VERSION "created by canmatrix"

NS_ :

BS_:

BU_: User ADM_PC_LL25 ADM_PC_BC25 ADM_PC_BP25 ADM_PC_BI25

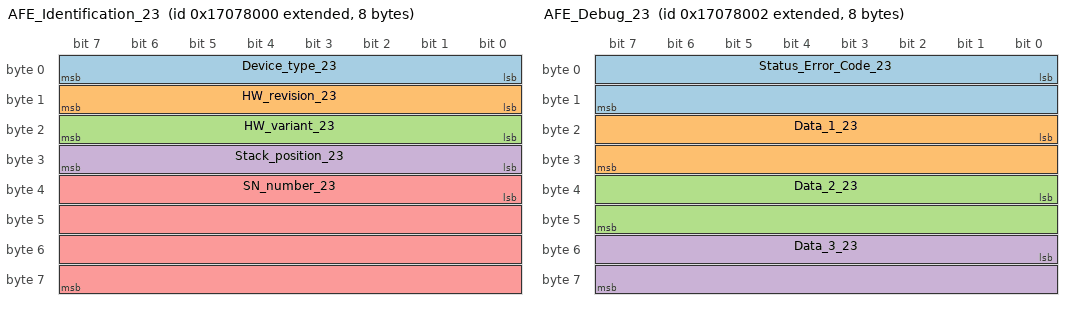
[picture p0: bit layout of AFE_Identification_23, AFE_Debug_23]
BO_ 2533851136 AFE_Identification_23: 8 ADM_PC_BP25
 SG_ Device_type_23 : 0|8@1+ (1,0) [0|255] "" Vector__XXX
 SG_ HW_revision_23 : 8|8@1+ (1,0) [0|255] "" Vector__XXX
 SG_ HW_variant_23 : 16|8@1+ (1,0) [0|255] "" Vector__XXX
 SG_ Stack_position_23 : 24|8@1+ (1,0) [0|255] "" Vector__XXX
 SG_ SN_number_23 : 32|32@1+ (1,0) [0|4294967295] "" Vector__XXX

BO_ 2533851137 AFE_FwInfo_23: 8 ADM_PC_BP25
 SG_ FW_info_mux_23 M : 56|8@1+ (1,0) [0|255] "" Vector__XXX
 SG_ FW_revision_0_23 m0 : 0|8@1+ (1,0) [0|255] "" Vector__XXX
 SG_ FW_revision_1_23 m0 : 8|8@1+ (1,0) [0|255] "" Vector__XXX
 SG_ FW_revision_2_23 m0 : 16|8@1+ (1,0) [0|255] "" Vector__XXX
 SG_ FW_revision_3_23 m0 : 24|8@1+ (1,0) [0|255] "" Vector__XXX
 SG_ FW_revision_4_23 m0 : 32|8@1+ (1,0) [0|255] "" Vector__XXX
 SG_ FW_revision_5_23 m0 : 40|8@1+ (1,0) [0|255] "" Vector__XXX
 SG_ FW_revision_6_23 m0 : 48|8@1+ (1,0) [0|255] "" Vector__XXX
 SG_ FW_revision_7_23 m1 : 0|8@1+ (1,0) [0|255] "" Vector__XXX
 SG_ FW_revision_8_23 m1 : 8|8@1+ (1,0) [0|255] "" Vector__XXX
 SG_ FW_revision_9_23 m1 : 16|8@1+ (1,0) [0|255] "" Vector__XXX
 SG_ FW_revision_10_23 m1 : 24|8@1+ (1,0) [0|255] "" Vector__XXX
 SG_ FW_revision_11_23 m1 : 32|8@1+ (1,0) [0|255] "" Vector__XXX
 SG_ FW_revision_12_23 m1 : 40|8@1+ (1,0) [0|255] "" Vector__XXX
 SG_ FW_revision_13_23 m1 : 48|8@1+ (1,0) [0|255] "" Vector__XXX
 SG_ FW_datecode_0_23 m2 : 0|8@1+ (1,0) [0|255] "" Vector__XXX
 SG_ FW_datecode_1_23 m2 : 8|8@1+ (1,0) [0|255] "" Vector__XXX
 SG_ FW_datecode_2_23 m2 : 16|8@1+ (1,0) [0|255] "" Vector__XXX
 SG_ FW_datecode_3_23 m2 : 24|8@1+ (1,0) [0|255] "" Vector__XXX
 SG_ FW_datecode_4_23 m2 : 32|8@1+ (1,0) [0|255] "" Vector__XXX
 SG_ FW_datecode_5_23 m2 : 40|8@1+ (1,0) [0|255] "" Vector__XXX
 SG_ FW_datecode_6_23 m2 : 48|8@1+ (1,0) [0|255] "" Vector__XXX
 SG_ FW_datecode_7_23 m3 : 0|8@1+ (1,0) [0|255] "" Vector__XXX
 SG_ FW_datecode_8_23 m3 : 8|8@1+ (1,0) [0|255] "" Vector__XXX
 SG_ FW_datecode_9_23 m3 : 16|8@1+ (1,0) [0|255] "" Vector__XXX
 SG_ FW_datecode_10_23 m3 : 24|8@1+ (1,0) [0|255] "" Vector__XXX
 SG_ FW_datecode_11_23 m3 : 32|8@1+ (1,0) [0|255] "" Vector__XXX
 SG_ FW_datecode_12_23 m3 : 40|8@1+ (1,0) [0|255] "" Vector__XXX
 SG_ FW_datecode_13_23 m3 : 48|8@1+ (1,0) [0|255] "" Vector__XXX

BO_ 2533851149 _AFE_Boot_FwInfo_23: 8 ADM_PC_BP25
 SG_ Boot_FW_info_mux_23 M : 56|8@1+ (1,0) [0|255] "" Vector__XXX
 SG_ FW_revision_0_23 m0 : 0|8@1+ (1,0) [0|255] "" Vector__XXX
 SG_ FW_revision_1_23 m0 : 8|8@1+ (1,0) [0|255] "" Vector__XXX
 SG_ FW_revision_2_23 m0 : 16|8@1+ (1,0) [0|255] "" Vector__XXX
 SG_ FW_revision_3_23 m0 : 24|8@1+ (1,0) [0|255] "" Vector__XXX
 SG_ FW_revision_4_23 m0 : 32|8@1+ (1,0) [0|255] "" Vector__XXX
 SG_ FW_revision_5_23 m0 : 40|8@1+ (1,0) [0|255] "" Vector__XXX
 SG_ FW_revision_6_23 m0 : 48|8@1+ (1,0) [0|255] "" Vector__XXX
 SG_ FW_revision_7_23 m1 : 0|8@1+ (1,0) [0|255] "" Vector__XXX
 SG_ FW_revision_8_23 m1 : 8|8@1+ (1,0) [0|255] "" Vector__XXX
 SG_ FW_revision_9_23 m1 : 16|8@1+ (1,0) [0|255] "" Vector__XXX
 SG_ FW_revision_10_23 m1 : 24|8@1+ (1,0) [0|255] "" Vector__XXX
 SG_ FW_revision_11_23 m1 : 32|8@1+ (1,0) [0|255] "" Vector__XXX
 SG_ FW_revision_12_23 m1 : 40|8@1+ (1,0) [0|255] "" Vector__XXX
 SG_ FW_revision_13_23 m1 : 48|8@1+ (1,0) [0|255] "" Vector__XXX
 SG_ FW_datecode_0_23 m2 : 0|8@1+ (1,0) [0|255] "" Vector__XXX
 SG_ FW_datecode_1_23 m2 : 8|8@1+ (1,0) [0|255] "" Vector__XXX
 SG_ FW_datecode_2_23 m2 : 16|8@1+ (1,0) [0|255] "" Vector__XXX
 SG_ FW_datecode_3_23 m2 : 24|8@1+ (1,0) [0|255] "" Vector__XXX
 SG_ FW_datecode_4_23 m2 : 32|8@1+ (1,0) [0|255] "" Vector__XXX
 SG_ FW_datecode_5_23 m2 : 40|8@1+ (1,0) [0|255] "" Vector__XXX
 SG_ FW_datecode_6_23 m2 : 48|8@1+ (1,0) [0|255] "" Vector__XXX
 SG_ FW_datecode_7_23 m3 : 0|8@1+ (1,0) [0|255] "" Vector__XXX
 SG_ FW_datecode_8_23 m3 : 8|8@1+ (1,0) [0|255] "" Vector__XXX
 SG_ FW_datecode_9_23 m3 : 16|8@1+ (1,0) [0|255] "" Vector__XXX
 SG_ FW_datecode_10_23 m3 : 24|8@1+ (1,0) [0|255] "" Vector__XXX
 SG_ FW_datecode_11_23 m3 : 32|8@1+ (1,0) [0|255] "" Vector__XXX
 SG_ FW_datecode_12_23 m3 : 40|8@1+ (1,0) [0|255] "" Vector__XXX
 SG_ FW_datecode_13_23 m3 : 48|8@1+ (1,0) [0|255] "" Vector__XXX

BO_ 2533851138 AFE_Debug_23: 8 ADM_PC_BP25
 SG_ Status_Error_Code_23 : 0|16@1+ (1,0) [0|65535] "" Vector__XXX
 SG_ Data_1_23 : 16|16@1+ (1,0) [0|65535] "" Vector__XXX
 SG_ Data_2_23 : 32|16@1+ (1,0) [0|65535] "" Vector__XXX
 SG_ Data_3_23 : 48|16@1+ (1,0) [0|65535] "" Vector__XXX

BO_ 2533851143 AFE_Status_23: 8 ADM_PC_BP25
 SG_ Running_23 : 0|1@1+ (1,0) [0|1] "" Vector__XXX
 SG_ PWM_23 : 1|1@1+ (1,0) [0|1] "" Vector__XXX
 SG_ Current_dc_loop_mode_23 : 2|1@1+ (1,0) [0|1] "" Vector__XXX
 SG_ Current_ac_loop_mode_23 : 3|1@1+ (1,0) [0|1] "" Vector__XXX
 SG_ Buck_23 : 5|1@1+ (1,0) [0|1] "" Vector__XXX
 SG_ Boost_23 : 6|1@1+ (1,0) [0|1] "" Vector__XXX
 SG_ Precharge_dc_buck_mode_23 : 7|1@1+ (1,0) [0|1] "" Vector__XXX
 SG_ Precharge_dc_boost_mode_23 : 8|1@1+ (1,0) [0|1] "" Vector__XXX
 SG_ Rectifier_3ph_23 : 9|1@1+ (1,0) [0|1] "" Vector__XXX
 SG_ Stack_mode_23 : 10|1@1+ (1,0) [0|1] "" Vector__XXX
 SG_ Master_23 : 11|1@1+ (1,0) [0|1] "" Vector__XXX
 SG_ Slave_23 : 12|1@1+ (1,0) [0|1] "" Vector__XXX
 SG_ Inverter_1ph_23 : 13|1@1+ (1,0) [0|1] "" Vector__XXX
 SG_ Boost_Neutral_23 : 14|1@1+ (1,0) [0|1] "" Vector__XXX
 SG_ Rectifier_1ph_23 : 15|1@1+ (1,0) [0|1] "" Vector__XXX
 SG_ Inverter_3ph_23 : 16|1@1+ (1,0) [0|1] "" Vector__XXX
 SG_ Ready_23 : 17|1@1+ (1,0) [0|1] "" Vector__XXX
 SG_ Inverter_1ph_Sync_23 : 18|1@1+ (1,0) [0|1] "" Vector__XXX
 SG_ Neutral_23 : 19|1@1+ (1,0) [0|1] "" Vector__XXX
 SG_ Rectifier_1ph_Buck_23 : 20|1@1+ (1,0) [0|1] "" Vector__XXX
 SG_ Inverter_1ph_Boost_23 : 21|1@1+ (1,0) [0|1] "" Vector__XXX
 SG_ Rectifier_distributed_23 : 22|1@1+ (1,0) [0|1] "" Vector__XXX
 SG_ MPPT_buck_23 : 23|1@1+ (1,0) [0|1] "" Vector__XXX
 SG_ MPPT_boost_23 : 24|1@1+ (1,0) [0|1] "" Vector__XXX
 SG_ Buck_2p_float_23 : 25|1@1+ (1,0) [0|1] "" Vector__XXX
 SG_ Inverter_1ph_Distributed_23 : 26|1@1+ (1,0) [0|1] "" Vector__XXX

BO_ 2533851142 AFE_Faults_23: 3 ADM_PC_BP25
 SG_ Protection_trip_internal_23 : 0|1@1+ (1,0) [0|1] "" Vector__XXX
 SG_ Protection_trip_external_23 : 1|1@1+ (1,0) [0|1] "" Vector__XXX
 SG_ Phase_U_overcurrent_23 : 2|1@1+ (1,0) [0|1] "" Vector__XXX
 SG_ Phase_U_overvoltage_23 : 3|1@1+ (1,0) [0|1] "" Vector__XXX
 SG_ Phase_U_undervoltage_23 : 4|1@1+ (1,0) [0|1] "" Vector__XXX
 SG_ Phase_V_overvoltage_23 : 5|1@1+ (1,0) [0|1] "" Vector__XXX
 SG_ Phase_V_undervoltage_23 : 6|1@1+ (1,0) [0|1] "" Vector__XXX
 SG_ Phase_V_overcurrent_23 : 7|1@1+ (1,0) [0|1] "" Vector__XXX
 SG_ Phase_W_overvoltage_23 : 8|1@1+ (1,0) [0|1] "" Vector__XXX
 SG_ Phase_W_undervoltage_23 : 9|1@1+ (1,0) [0|1] "" Vector__XXX
 SG_ Phase_W_overcurrent_23 : 10|1@1+ (1,0) [0|1] "" Vector__XXX
 SG_ DC_undervoltage_23 : 11|1@1+ (1,0) [0|1] "" Vector__XXX
 SG_ DC_overvoltage_23 : 12|1@1+ (1,0) [0|1] "" Vector__XXX
 SG_ MOSFET_overtemperature_23 : 13|1@1+ (1,0) [0|1] "" Vector__XXX
 SG_ Inductor_overtemperature_23 : 14|1@1+ (1,0) [0|1] "" Vector__XXX
 SG_ Keep_Alive_not_served_23 : 15|1@1+ (1,0) [0|1] "" Vector__XXX
 SG_ PLL_not_locked_23 : 16|1@1+ (1,0) [0|1] "" Vector__XXX
 SG_ NFO_23 : 20|1@1+ (1,0) [0|1] "" Vector__XXX
 SG_ Measurement_system_failure_23 : 21|1@1+ (1,0) [0|1] "" Vector__XXX
 SG_ EEPROM_failure_23 : 22|1@1+ (1,0) [0|1] "" Vector__XXX
 SG_ System_23 : 23|1@1+ (1,0) [0|1] "" Vector__XXX

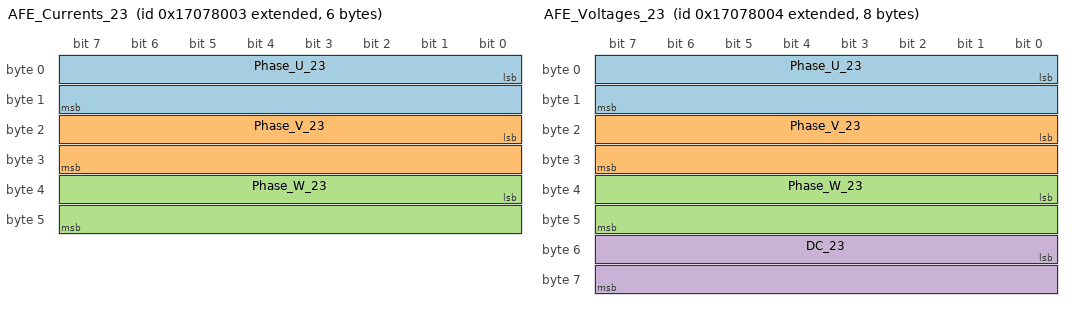
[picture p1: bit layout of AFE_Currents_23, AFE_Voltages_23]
BO_ 2533851139 AFE_Currents_23: 6 ADM_PC_BP25
 SG_ Phase_U_23 : 0|16@1- (0.01,0) [-327.68|327.67] "A" Vector__XXX
 SG_ Phase_V_23 : 16|16@1- (0.01,0) [-327.68|327.67] "A" Vector__XXX
 SG_ Phase_W_23 : 32|16@1- (0.01,0) [-327.68|327.67] "A" Vector__XXX

BO_ 2533851152 AFE_DC_Bus_current_23: 2 ADM_PC_BP25
 SG_ Bus_current_23 : 0|16@1- (0.01,0) [-327.68|327.67] "A" Vector__XXX

BO_ 2533851150 _AFE_Broadcast_23: 8 ADM_PC_BP25
 SG_ Diagnostics_Index_23 M : 56|8@1+ (1,0) [0|255] "" Vector__XXX
 SG_ Phase_U_23 m1 : 8|16@1- (0.01,0) [-327.68|327.67] "A" ADM_PC_BP25
 SG_ Phase_V_23 m1 : 24|16@1- (0.01,0) [-327.68|327.67] "A" ADM_PC_BP25
 SG_ Phase_W_23 m1 : 40|16@1- (0.01,0) [-327.68|327.67] "A" ADM_PC_BP25
 SG_ Stack_position_23 : 0|5@1+ (1,0) [0|31] "" ADM_PC_BP25
 SG_ Group_ID_23 : 5|3@1+ (1,0) [0|7] "" ADM_PC_BP25

BO_ 2533851140 AFE_Voltages_23: 8 ADM_PC_BP25
 SG_ Phase_U_23 : 0|16@1- (0.1,0) [-3276.8|3276.7] "V" Vector__XXX
 SG_ Phase_V_23 : 16|16@1- (0.1,0) [-3276.8|3276.7] "V" Vector__XXX
 SG_ Phase_W_23 : 32|16@1- (0.1,0) [-3276.8|3276.7] "V" Vector__XXX
 SG_ DC_23 : 48|16@1- (0.1,0) [-3276.8|3276.7] "V" Vector__XXX

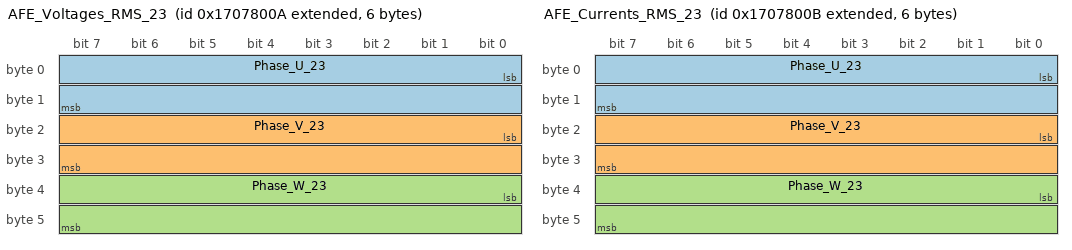
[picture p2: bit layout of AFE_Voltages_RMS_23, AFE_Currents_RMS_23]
BO_ 2533851146 AFE_Voltages_RMS_23: 6 ADM_PC_BP25
 SG_ Phase_U_23 : 0|16@1+ (0.1,0) [0|6553.5] "V" Vector__XXX
 SG_ Phase_V_23 : 16|16@1+ (0.1,0) [0|6553.5] "V" Vector__XXX
 SG_ Phase_W_23 : 32|16@1+ (0.1,0) [0|6553.5] "V" Vector__XXX

BO_ 2533851147 AFE_Currents_RMS_23: 6 ADM_PC_BP25
 SG_ Phase_U_23 : 0|16@1+ (0.01,0) [0.00|655.35] "A" Vector__XXX
 SG_ Phase_V_23 : 16|16@1+ (0.01,0) [0.00|655.35] "A" Vector__XXX
 SG_ Phase_W_23 : 32|16@1+ (0.01,0) [0.00|655.35] "A" Vector__XXX

BO_ 2533851148 AFE_Mains_23: 4 ADM_PC_BP25
 SG_ Frequency_23 : 0|16@1+ (0.01,0) [0.00|655.35] "Hz" Vector__XXX
 SG_ Phase_23 : 16|16@1- (0.1,0) [-3276.8|3276.7] "Deg." Vector__XXX

BO_ 2533851141 AFE_Temperatures_23: 4 ADM_PC_BP25
 SG_ Temp_Bridge_23 : 0|16@1- (0.01,0) [-327.68|327.67] "°C" Vector__XXX
 SG_ Temp_Inductors_23 : 16|16@1- (0.01,0) [-327.68|327.67] "°C" Vector__XXX

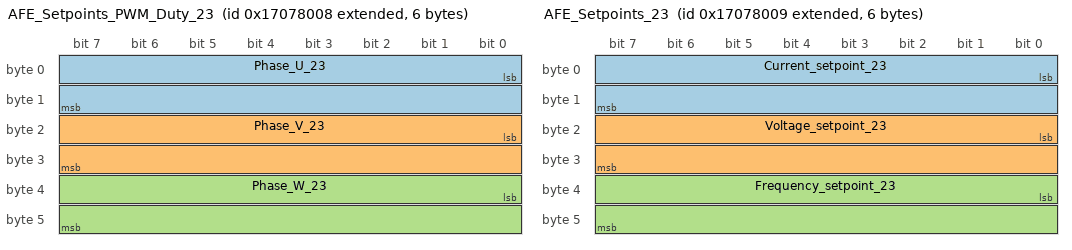
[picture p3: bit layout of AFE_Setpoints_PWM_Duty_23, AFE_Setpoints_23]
BO_ 2533851144 AFE_Setpoints_PWM_Duty_23: 6 ADM_PC_BP25
 SG_ Phase_U_23 : 0|16@1+ (0.001525902,0) [0E-009|99.999987570] "%" Vector__XXX
 SG_ Phase_V_23 : 16|16@1+ (0.001525902,0) [0E-009|99.999987570] "%" Vector__XXX
 SG_ Phase_W_23 : 32|16@1+ (0.001525902,0) [0E-009|99.999987570] "%" Vector__XXX

BO_ 2533851145 AFE_Setpoints_23: 6 ADM_PC_BP25
 SG_ Current_setpoint_23 : 0|16@1- (0.01,0) [-327.68|327.67] "A" Vector__XXX
 SG_ Voltage_setpoint_23 : 16|16@1+ (0.1,0) [0|6553.5] "V" Vector__XXX
 SG_ Frequency_setpoint_23 : 32|16@1+ (0.01,0) [0.00|655.35] "Hz" Vector__XXX

BO_ 2533818464 AFE_Keep_Alive_23: 1 User
 SG_ Keep_Alive_Enable_23 : 0|1@1+ (1,0) [0|1] "" ADM_PC_BP25

BO_ 2533818432 AFE_Mode_Control_23: 8 User
 SG_ Converter_ON_23 : 0|1@1+ (1,0) [0|1] "" ADM_PC_BP25
 SG_ PWM_ON_23 : 1|1@1+ (1,0) [0|1] "" ADM_PC_BP25
 SG_ DC_Current_feedback_ON_23 : 2|1@1+ (1,0) [0|1] "" ADM_PC_BP25
 SG_ AC_Current_feedback_ON_23 : 3|1@1+ (1,0) [0|1] "" ADM_PC_BP25
 SG_ Buck_ON_23 : 5|1@1+ (1,0) [0|1] "" ADM_PC_BP25
 SG_ Boost_ON_23 : 6|1@1+ (1,0) [0|1] "" ADM_PC_BP25
 SG_ Rectifier_3ph_ON_23 : 9|1@1+ (1,0) [0|1] "" ADM_PC_BP25
 SG_ Inverter_1ph_ON_23 : 10|1@1+ (1,0) [0|1] "" ADM_PC_BP25
 SG_ Rectifier_1ph_ON_23 : 11|1@1+ (1,0) [0|1] "" ADM_PC_BP25
 SG_ Boost_Neutral_ON_23 : 12|1@1+ (1,0) [0|1] "" ADM_PC_BP25
 SG_ Inverter_3ph_ON_23 : 13|1@1+ (1,0) [0|1] "" ADM_PC_BP25
 SG_ Inverter_1ph_Sync_ON_23 : 14|1@1+ (1,0) [0|1] "" ADM_PC_BP25
 SG_ Neutral_ON_23 : 15|1@1+ (1,0) [0|1] "" ADM_PC_BP25
 SG_ Rectifier_1ph_Buck_ON_23 : 16|1@1+ (1,0) [0|1] "" ADM_PC_BP25
 SG_ Inverter_1ph_Boost_ON_23 : 17|1@1+ (1,0) [0|1] "" ADM_PC_BP25
 SG_ Rectifier_Distributed_ON_23 : 18|1@1+ (1,0) [0|1] "" ADM_PC_BP25
 SG_ MPPT_buck_ON_23 : 19|1@1+ (1,0) [0|1] "" ADM_PC_BP25
 SG_ MPPT_boost_ON_23 : 20|1@1+ (1,0) [0|1] "" ADM_PC_BP25
 SG_ Buck_2p_float_ON_23 : 21|1@1+ (1,0) [0|1] "" ADM_PC_BP25
 SG_ Inverter_1ph_Distributed_ON_23 : 22|1@1+ (1,0) [0|1] "" ADM_PC_BP25

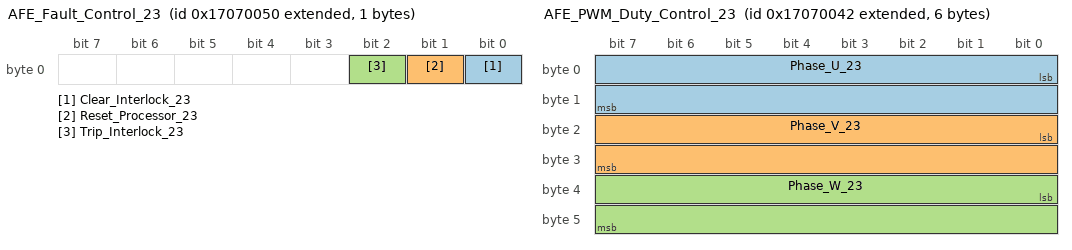
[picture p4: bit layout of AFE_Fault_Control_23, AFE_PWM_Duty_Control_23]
BO_ 2533818448 AFE_Fault_Control_23: 1 User
 SG_ Clear_Interlock_23 : 0|1@1+ (1,0) [0|1] "" ADM_PC_BP25
 SG_ Reset_Processor_23 : 1|1@1+ (1,0) [0|1] "" ADM_PC_BP25
 SG_ Trip_Interlock_23 : 2|1@1+ (1,0) [0|1] "" ADM_PC_BP25

BO_ 2533818433 AFE_Reactive_Current_Setpoint_Co: 2 User
 SG_ Reactive_current_setpoint_23 : 0|16@1- (0.01,0) [-150|150] "A" ADM_PC_BP25

BO_ 2533818434 AFE_PWM_Duty_Control_23: 6 User
 SG_ Phase_U_23 : 0|16@1+ (0.001525902,0) [0E-009|99.999987570] "%" ADM_PC_BP25
 SG_ Phase_V_23 : 16|16@1+ (0.001525902,0) [0E-009|99.999987570] "%" ADM_PC_BP25
 SG_ Phase_W_23 : 32|16@1+ (0.001525902,0) [0E-009|99.999987570] "%" ADM_PC_BP25

BO_ 2533818435 AFE_Current_Setpoint_Control_23: 2 User
 SG_ Current_setpoint_23 : 0|16@1- (0.01,0) [-150|150] "A" ADM_PC_BP25

BO_ 2533818436 AFE_Voltage_Setpoint_Control_23: 2 User
 SG_ Voltage_setpoint_23 : 0|16@1+ (0.1,0) [0|1500] "V" ADM_PC_BP25

BO_ 2533818440 AFE_Frequency_Setpoint_Control_2: 2 User
 SG_ Frequency_setpoint_23 : 0|16@1+ (0.01,0) [40|70] "Hz" ADM_PC_BP25

BO_ 2533818441 AFE_Phase_Setpoint_Control_23: 2 User
 SG_ Phase_setpoint_23 : 0|16@1+ (1,0) [0|360] "deg" ADM_PC_BP25

BO_ 2533818480 AFE_Rectifier_Setpoint_Control_2: 8 User
 SG_ Voltage_setpoint_2_23 : 0|16@1+ (0.1,0) [0|1500] "V" ADM_PC_BP25
 SG_ Current_setpoint_2_23 : 16|16@1- (0.01,0) [-150|150] "A" ADM_PC_BP25

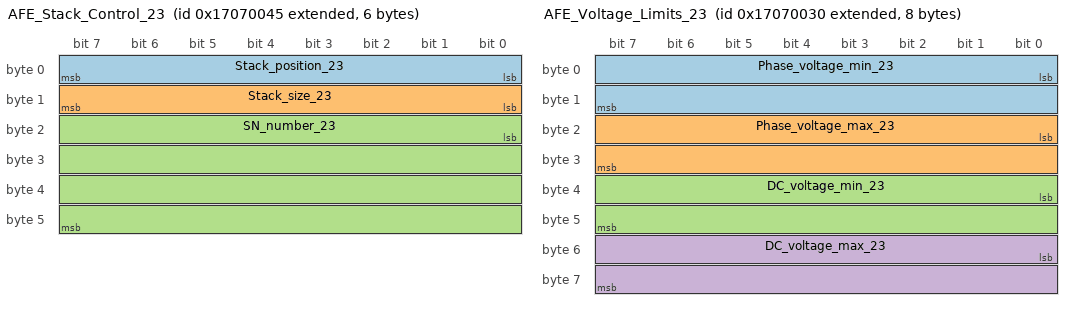
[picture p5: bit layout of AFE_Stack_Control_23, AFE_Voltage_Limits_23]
BO_ 2533818437 AFE_Stack_Control_23: 6 User
 SG_ Stack_position_23 : 0|8@1+ (1,0) [0|255] "" ADM_PC_BP25
 SG_ Stack_size_23 : 8|8@1+ (1,0) [0|255] "" ADM_PC_BP25
 SG_ SN_number_23 : 16|32@1+ (1,0) [0|4294967295] "" ADM_PC_BP25

BO_ 2533818416 AFE_Voltage_Limits_23: 8 User
 SG_ Phase_voltage_min_23 : 0|16@1- (0.1,0) [0|3276.7] "V" ADM_PC_BP25
 SG_ Phase_voltage_max_23 : 16|16@1- (0.1,0) [-3276.8|850] "V" ADM_PC_BP25
 SG_ DC_voltage_min_23 : 32|16@1- (0.1,0) [0|3276.7] "V" ADM_PC_BP25
 SG_ DC_voltage_max_23 : 48|16@1- (0.1,0) [-3276.8|850] "V" ADM_PC_BP25

BO_ 2533818417 AFE_Current_Limits_23: 4 User
 SG_ Phase_current_min_23 : 0|16@1- (0.01,0) [-60|60] "A" ADM_PC_BP25
 SG_ Phase_current_max_23 : 16|16@1- (0.01,0) [-60|60] "A" ADM_PC_BP25

BO_ 2533818444 AFE_Group_Control_23: 1 User
 SG_ Group_ID_23 : 0|8@1+ (1,0) [0|255] "" ADM_PC_BP25

BO_ 2533851151 AFE_Group_Info_23: 1 ADM_PC_BP25
 SG_ Group_ID_23 : 0|8@1+ (1,0) [0|255] "" Vector__XXX

BO_ 2533818465 AFE_System_Flags_Control_23: 8 User
 SG_ Factory_mode_23 : 0|1@1+ (1,0) [0|1] "" ADM_PC_BP25
 SG_ Silent_CAN_mode_23 : 1|1@1+ (1,0) [0|1] "" ADM_PC_BP25

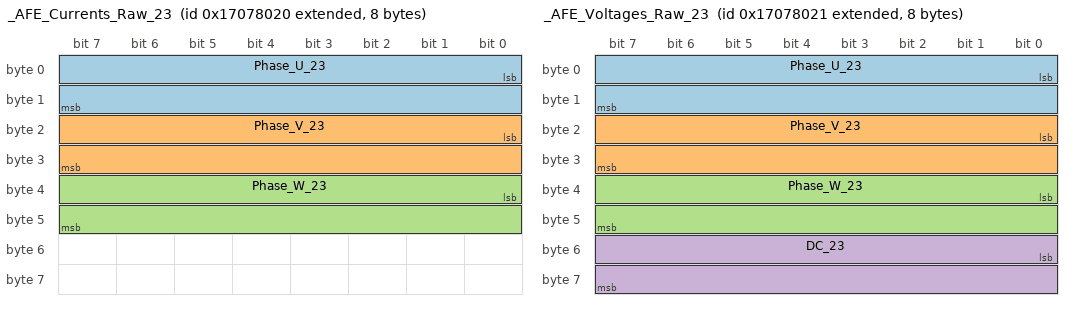
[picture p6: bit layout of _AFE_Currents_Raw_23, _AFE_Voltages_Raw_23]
BO_ 2533851168 _AFE_Currents_Raw_23: 8 ADM_PC_BP25
 SG_ Phase_U_23 : 0|16@1- (1,0) [-32768|32767] "" Vector__XXX
 SG_ Phase_V_23 : 16|16@1- (1,0) [-32768|32767] "" Vector__XXX
 SG_ Phase_W_23 : 32|16@1- (1,0) [-32768|32767] "" Vector__XXX

BO_ 2533851169 _AFE_Voltages_Raw_23: 8 ADM_PC_BP25
 SG_ Phase_U_23 : 0|16@1- (1,0) [-32768|32767] "" Vector__XXX
 SG_ Phase_V_23 : 16|16@1- (1,0) [-32768|32767] "" Vector__XXX
 SG_ Phase_W_23 : 32|16@1- (1,0) [-32768|32767] "" Vector__XXX
 SG_ DC_23 : 48|16@1- (1,0) [-32768|32767] "" Vector__XXX

BO_ 2533818442 _AFE_ADC_Calibration_Mode_23: 1 User
 SG_ Calibration_Index_23 M : 2|5@1+ (1,0) [0|31] "" Vector__XXX
 SG_ Current_U_23 m1 : 0|2@1+ (1,0) [0|3] "" ADM_PC_BP25
 SG_ Current_V_23 m2 : 0|2@1+ (1,0) [0|3] "" ADM_PC_BP25
 SG_ Current_W_23 m3 : 0|2@1+ (1,0) [0|3] "" ADM_PC_BP25
 SG_ Voltage_U_23 m4 : 0|2@1+ (1,0) [0|3] "" ADM_PC_BP25
 SG_ Voltage_V_23 m5 : 0|2@1+ (1,0) [0|3] "" ADM_PC_BP25
 SG_ Voltage_W_23 m6 : 0|2@1+ (1,0) [0|3] "" ADM_PC_BP25
 SG_ Voltage_DC_23 m7 : 0|2@1+ (1,0) [0|3] "" ADM_PC_BP25
 SG_ start_23 : 7|1@1+ (1,0) [0|1] "" ADM_PC_BP25

BO_ 2533818443 _AFE_ADC_Calibration_Setpoint_23: 3 User
 SG_ Calibration_Index_23 M : 16|5@1+ (1,0) [0|31] "" Vector__XXX
 SG_ Current_U_23 m1 : 0|16@1- (0.01,0) [-100|100] "A" ADM_PC_BP25
 SG_ Current_V_23 m2 : 0|16@1- (0.01,0) [-100|100] "A" ADM_PC_BP25
 SG_ Current_W_23 m3 : 0|16@1- (0.01,0) [-100|100] "A" ADM_PC_BP25
 SG_ Voltage_U_23 m4 : 0|16@1+ (0.1,0) [0|1500] "V" ADM_PC_BP25
 SG_ Voltage_V_23 m5 : 0|16@1+ (0.1,0) [0|1500] "V" ADM_PC_BP25
 SG_ Voltage_W_23 m6 : 0|16@1+ (0.1,0) [0|1500] "V" ADM_PC_BP25
 SG_ Voltage_DC_23 m7 : 0|16@1+ (0.1,0) [0|1500] "V" ADM_PC_BP25
 SG_ point_23 : 21|3@1+ (1,0) [0|7] "" ADM_PC_BP25

BO_ 2533818438 _AFE_Calibration_Offset_Update_2: 6 User
 SG_ Calibration_Index_23 M : 16|16@1+ (1,0) [0|65535] "" Vector__XXX
 SG_ Current_U_23 m0 : 0|16@1- (1,0) [-32768|32767] "ADC Counts" ADM_PC_BP25
 SG_ Current_V_23 m1 : 0|16@1- (1,0) [-32768|32767] "ADC Counts" ADM_PC_BP25
 SG_ Current_W_23 m2 : 0|16@1- (1,0) [-32768|32767] "ADC Counts" ADM_PC_BP25
 SG_ Voltage_U_23 m3 : 0|16@1- (1,0) [-32768|32767] "ADC Counts" ADM_PC_BP25
 SG_ Voltage_V_23 m4 : 0|16@1- (1,0) [-32768|32767] "ADC Counts" ADM_PC_BP25
 SG_ Voltage_W_23 m5 : 0|16@1- (1,0) [-32768|32767] "ADC Counts" ADM_PC_BP25
 SG_ Voltage_DC_23 m6 : 0|16@1- (1,0) [-32768|32767] "ADC Counts" ADM_PC_BP25
 SG_ CRC_23 : 32|16@1+ (1,0) [0|65535] "-" ADM_PC_BP25

BO_ 2533818439 _AFE_Calibration_Scale_Update_23: 6 User
 SG_ Calibration_Index_23 M : 16|16@1+ (1,0) [0|65535] "" Vector__XXX
 SG_ Current_U_23 m0 : 0|16@1- (0.0000152587890625,0) [-0.5000000000000000|0.4999847412109375] "scale = 1.0 + value" ADM_PC_BP25
 SG_ Current_V_23 m1 : 0|16@1- (0.0000152587890625,0) [-0.5000000000000000|0.4999847412109375] "scale = 1.0 + value" ADM_PC_BP25
 SG_ Current_W_23 m2 : 0|16@1- (0.0000152587890625,0) [-0.5000000000000000|0.4999847412109375] "scale = 1.0 + value" ADM_PC_BP25
 SG_ Voltage_U_23 m3 : 0|16@1- (0.0000152587890625,0) [-0.5000000000000000|0.4999847412109375] "scale = 1.0 + value" ADM_PC_BP25
 SG_ Voltage_V_23 m4 : 0|16@1- (0.0000152587890625,0) [-0.5000000000000000|0.4999847412109375] "scale = 1.0 + value" ADM_PC_BP25
 SG_ Voltage_W_23 m5 : 0|16@1- (0.0000152587890625,0) [-0.5000000000000000|0.4999847412109375] "scale = 1.0 + value" ADM_PC_BP25
 SG_ Voltage_DC_23 m6 : 0|16@1- (0.0000152587890625,0) [-0.5000000000000000|0.4999847412109375] "scale = 1.0 + value" ADM_PC_BP25
 SG_ CRC_23 : 32|16@1+ (1,0) [0|65535] "-" ADM_PC_BP25

BO_ 2533851217 _AFE_Calibration_Adc_Scale_23: 6 ADM_PC_BP25
 SG_ Adc_Index_23 M : 32|16@1+ (1,0) [0|65535] "" Vector__XXX
 SG_ Current_U_23 m0 : 0|32@1+ (1,0) [0|4294967295] "1 / adc_bins" User
 SG_ Current_V_23 m1 : 0|32@1+ (1,0) [0|4294967295] "1 / adc_bins" User
 SG_ Current_W_23 m2 : 0|32@1+ (1,0) [0|4294967295] "1 / adc_bins" User
 SG_ Voltage_U_23 m3 : 0|32@1+ (1,0) [0|4294967295] "1 / adc_bins" User
 SG_ Voltage_V_23 m4 : 0|32@1+ (1,0) [0|4294967295] "1 / adc_bins" User
 SG_ Voltage_W_23 m5 : 0|32@1+ (1,0) [0|4294967295] "1 / adc_bins" User
 SG_ Voltage_DC_23 m6 : 0|32@1+ (1,0) [0|4294967295] "1 / adc_bins" User

BO_ 2533851218 _AFE_Calibration_Adc_Fs_23: 6 ADM_PC_BP25
 SG_ Adc_Index_23 M : 32|16@1+ (1,0) [0|65535] "" Vector__XXX
 SG_ Current_U_23 m0 : 0|32@1+ (1,0) [0|4294967295] "Fullscale" User
 SG_ Current_V_23 m1 : 0|32@1+ (1,0) [0|4294967295] "Fullscale" User
 SG_ Current_W_23 m2 : 0|32@1+ (1,0) [0|4294967295] "Fullscale" User
 SG_ Voltage_U_23 m3 : 0|32@1+ (1,0) [0|4294967295] "Fullscale" User
 SG_ Voltage_V_23 m4 : 0|32@1+ (1,0) [0|4294967295] "Fullscale" User
 SG_ Voltage_W_23 m5 : 0|32@1+ (1,0) [0|4294967295] "Fullscale" User
 SG_ Voltage_DC_23 m6 : 0|32@1+ (1,0) [0|4294967295] "Fullscale" User

BO_ 2533851219 _AFE_Calibration_Adc_Offset_23: 4 ADM_PC_BP25
 SG_ Adc_Index_23 M : 16|16@1+ (1,0) [0|65535] "" Vector__XXX
 SG_ Current_U_23 m0 : 0|16@1- (1,0) [-32768|32767] "-" User
 SG_ Current_V_23 m1 : 0|16@1- (1,0) [-32768|32767] "-" User
 SG_ Current_W_23 m2 : 0|16@1- (1,0) [-32768|32767] "-" User
 SG_ Voltage_U_23 m3 : 0|16@1- (1,0) [-32768|32767] "-" User
 SG_ Voltage_V_23 m4 : 0|16@1- (1,0) [-32768|32767] "-" User
 SG_ Voltage_W_23 m5 : 0|16@1- (1,0) [-32768|32767] "-" User
 SG_ Voltage_DC_23 m6 : 0|16@1- (1,0) [-32768|32767] "-" User

BO_ 2533851220 _AFE_Calibration_Adc_Gain_23: 4 ADM_PC_BP25
 SG_ Adc_Index_23 M : 16|16@1+ (1,0) [0|65535] "" Vector__XXX
 SG_ Current_U_23 m0 : 0|16@1- (1,0) [-32768|32767] "-" User
 SG_ Current_V_23 m1 : 0|16@1- (1,0) [-32768|32767] "-" User
 SG_ Current_W_23 m2 : 0|16@1- (1,0) [-32768|32767] "-" User
 SG_ Voltage_U_23 m3 : 0|16@1- (1,0) [-32768|32767] "-" User
 SG_ Voltage_V_23 m4 : 0|16@1- (1,0) [-32768|32767] "-" User
 SG_ Voltage_W_23 m5 : 0|16@1- (1,0) [-32768|32767] "-" User
 SG_ Voltage_DC_23 m6 : 0|16@1- (1,0) [-32768|32767] "-" User

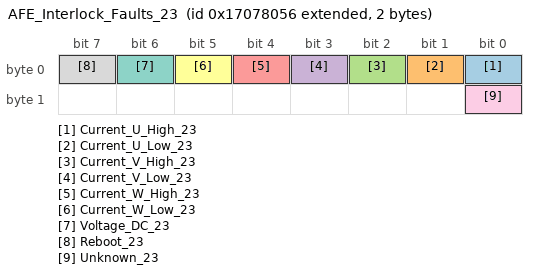
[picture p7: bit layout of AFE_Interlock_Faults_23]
BO_ 2533851222 AFE_Interlock_Faults_23: 2 ADM_PC_BP25
 SG_ Current_U_High_23 : 0|1@1+ (1,0) [0|1] "" Vector__XXX
 SG_ Current_U_Low_23 : 1|1@1+ (1,0) [0|1] "" Vector__XXX
 SG_ Current_V_High_23 : 2|1@1+ (1,0) [0|1] "" Vector__XXX
 SG_ Current_V_Low_23 : 3|1@1+ (1,0) [0|1] "" Vector__XXX
 SG_ Current_W_High_23 : 4|1@1+ (1,0) [0|1] "" Vector__XXX
 SG_ Current_W_Low_23 : 5|1@1+ (1,0) [0|1] "" Vector__XXX
 SG_ Voltage_DC_23 : 6|1@1+ (1,0) [0|1] "" Vector__XXX
 SG_ Reboot_23 : 7|1@1+ (1,0) [0|1] "" Vector__XXX
 SG_ Unknown_23 : 8|1@1+ (1,0) [0|1] "" Vector__XXX

BO_TX_BU_ 2533818432 : User,ADM_PC_LL25,ADM_PC_BC25,ADM_PC_BI25;
BO_TX_BU_ 2533818435 : User,ADM_PC_LL25,ADM_PC_BC25,ADM_PC_BI25;
BO_TX_BU_ 2533818436 : User,ADM_PC_LL25,ADM_PC_BC25,ADM_PC_BI25;
CM_ BO_ 2533851136  "Identification of the device";
CM_ BO_ 2533851137  "Git revision of the DSP firmware";
CM_ BO_ 2533851149  "Git revision of the bootloader firmware.";
CM_ BO_ 2533851138  "Values for debugging of HW/SW problems";
CM_ BO_ 2533851143  "Status bitfield";
CM_ BO_ 2533851142  "Fault bitfield";
CM_ BO_ 2533851139  "Current of phases U, V, W";
CM_ BO_ 2533851152  "Current of of the DC Bus";
CM_ BO_ 2533851150  "All AFEs will listen to this message";
CM_ BO_ 2533851147  "RMS Current of phases U, V, W";
CM_ BO_ 2533851148  "Three-Phase mains health (frequency, phase...)";
CM_ BO_ 2533851141  "Readouts of the module temperature sensors";
CM_ BO_ 2533851144  "Setpoints";
CM_ BO_ 2533851145  "Setpoints";
CM_ BO_ 2533818464  "Keep alive ping message. ";
CM_ BO_ 2533818432  "Operation Mode control: sets the converter operation mode";
CM_ BO_ 2533818448  "Fault Control: actions to clear faults and reset the system";
CM_ BO_ 2533818433  "Reactive power setpoint control.";
CM_ BO_ 2533818434  "PWM duty cycle control";
CM_ BO_ 2533818435  "Current setpoint control";
CM_ BO_ 2533818436  "Voltage setpoint control";
CM_ BO_ 2533818440  "Frequency setpoint control";
CM_ BO_ 2533818441  "Phase setpoint control";
CM_ BO_ 2533818480  "Additional voltage and current setpoints in single-phase rectifier and inverter control modes.";
CM_ BO_ 2533818437  "PFC stack control";
CM_ BO_ 2533818416  "Set the input and output voltage limits (minimum and maximum)";
CM_ BO_ 2533818417  "Set the output current limits (mminimum and maximum)";
CM_ BO_ 2533818444  "Set the Group ID of the device";
CM_ BO_ 2533851151  "Contains the Group ID of the device";
CM_ BO_ 2533818465  "Control the system flags";
CM_ BO_ 2533851168  "Current of phases A and B";
CM_ BO_ 2533851169  "Current of phases A and B";
CM_ BO_ 2533818442  "Automatic ADC calibration.";
CM_ BO_ 2533818443  "Setpoint for automatic ADC calibration.";
CM_ BO_ 2533818438  "Update of the calibration table for offsets.";
CM_ BO_ 2533818439  "Update of the calibration table for scales.";
CM_ BO_ 2533851217  "
                Adc scale (resolution) value of readouts.
            ";
CM_ BO_ 2533851218  "
                Adc fullscale value of readouts.
            ";
CM_ BO_ 2533851219  "
                Readout of ADC calibration data (offset) from EEPROM.
            ";
CM_ BO_ 2533851220  "
                Readout of ADC calibration data (gain) from EEPROM.
            ";
CM_ BO_ 2533851222  "Fault bitfield";

CM_ SG_ 2533851136 Device_type_23 "The device identification field, uniquely identifies the sender in the network";
CM_ SG_ 2533851136 HW_revision_23 "The hardware revision number";
CM_ SG_ 2533851136 HW_variant_23 "The DSP firmware revision number";
CM_ SG_ 2533851136 Stack_position_23 "Position of the module within the stack";
CM_ SG_ 2533851136 SN_number_23 "Unique module serial number";
CM_ SG_ 2533851137 FW_revision_0_23 "Character 0";
CM_ SG_ 2533851137 FW_revision_1_23 "Character 1";
CM_ SG_ 2533851137 FW_revision_2_23 "Character 2";
CM_ SG_ 2533851137 FW_revision_3_23 "Character 3";
CM_ SG_ 2533851137 FW_revision_4_23 "Character 3";
CM_ SG_ 2533851137 FW_revision_5_23 "Character 3";
CM_ SG_ 2533851137 FW_revision_6_23 "Character 3";
CM_ SG_ 2533851137 FW_revision_7_23 "Character 7";
CM_ SG_ 2533851137 FW_revision_8_23 "Character 8";
CM_ SG_ 2533851137 FW_revision_9_23 "Character 9";
CM_ SG_ 2533851137 FW_revision_10_23 "Character 10";
CM_ SG_ 2533851137 FW_revision_11_23 "Character 11";
CM_ SG_ 2533851137 FW_revision_12_23 "Character 12";
CM_ SG_ 2533851137 FW_revision_13_23 "Character 13";
CM_ SG_ 2533851137 FW_datecode_0_23 "Character 0";
CM_ SG_ 2533851137 FW_datecode_1_23 "Character 1";
CM_ SG_ 2533851137 FW_datecode_2_23 "Character 2";
CM_ SG_ 2533851137 FW_datecode_3_23 "Character 3";
CM_ SG_ 2533851137 FW_datecode_4_23 "Character 3";
CM_ SG_ 2533851137 FW_datecode_5_23 "Character 3";
CM_ SG_ 2533851137 FW_datecode_6_23 "Character 3";
CM_ SG_ 2533851137 FW_datecode_7_23 "Character 7";
CM_ SG_ 2533851137 FW_datecode_8_23 "Character 8";
CM_ SG_ 2533851137 FW_datecode_9_23 "Character 9";
CM_ SG_ 2533851137 FW_datecode_10_23 "Character 10";
CM_ SG_ 2533851137 FW_datecode_11_23 "Character 11";
CM_ SG_ 2533851137 FW_datecode_12_23 "Character 12";
CM_ SG_ 2533851137 FW_datecode_13_23 "Character 13";
CM_ SG_ 2533851149 FW_revision_0_23 "Character 0";
CM_ SG_ 2533851149 FW_revision_1_23 "Character 1";
CM_ SG_ 2533851149 FW_revision_2_23 "Character 2";
CM_ SG_ 2533851149 FW_revision_3_23 "Character 3";
CM_ SG_ 2533851149 FW_revision_4_23 "Character 3";
CM_ SG_ 2533851149 FW_revision_5_23 "Character 3";
CM_ SG_ 2533851149 FW_revision_6_23 "Character 3";
CM_ SG_ 2533851149 FW_revision_7_23 "Character 7";
CM_ SG_ 2533851149 FW_revision_8_23 "Character 8";
CM_ SG_ 2533851149 FW_revision_9_23 "Character 9";
CM_ SG_ 2533851149 FW_revision_10_23 "Character 10";
CM_ SG_ 2533851149 FW_revision_11_23 "Character 11";
CM_ SG_ 2533851149 FW_revision_12_23 "Character 12";
CM_ SG_ 2533851149 FW_revision_13_23 "Character 13";
CM_ SG_ 2533851149 FW_datecode_0_23 "Character 0";
CM_ SG_ 2533851149 FW_datecode_1_23 "Character 1";
CM_ SG_ 2533851149 FW_datecode_2_23 "Character 2";
CM_ SG_ 2533851149 FW_datecode_3_23 "Character 3";
CM_ SG_ 2533851149 FW_datecode_4_23 "Character 3";
CM_ SG_ 2533851149 FW_datecode_5_23 "Character 3";
CM_ SG_ 2533851149 FW_datecode_6_23 "Character 3";
CM_ SG_ 2533851149 FW_datecode_7_23 "Character 7";
CM_ SG_ 2533851149 FW_datecode_8_23 "Character 8";
CM_ SG_ 2533851149 FW_datecode_9_23 "Character 9";
CM_ SG_ 2533851149 FW_datecode_10_23 "Character 10";
CM_ SG_ 2533851149 FW_datecode_11_23 "Character 11";
CM_ SG_ 2533851149 FW_datecode_12_23 "Character 12";
CM_ SG_ 2533851149 FW_datecode_13_23 "Character 13";
CM_ SG_ 2533851138 Status_Error_Code_23 "Main status / error code as defined in errno/errno.h";
CM_ SG_ 2533851138 Data_1_23 "Additional information for the error/status";
CM_ SG_ 2533851138 Data_2_23 "Additional information for the error/status";
CM_ SG_ 2533851138 Data_3_23 "Additional information for the error/status";
CM_ SG_ 2533851143 Running_23 "Indicates if converter is running.";
CM_ SG_ 2533851143 PWM_23 "Indicates if converter is in PWM control mode.";
CM_ SG_ 2533851143 Current_dc_loop_mode_23 "Indicates if the current DC loop is enabled.";
CM_ SG_ 2533851143 Current_ac_loop_mode_23 "Indicates if the current AC loop is enabled.";
CM_ SG_ 2533851143 Buck_23 "Indicates if converter is in buck control mode.";
CM_ SG_ 2533851143 Boost_23 "Indicates if converter is in boost control mode.";
CM_ SG_ 2533851143 Precharge_dc_buck_mode_23 "Indicates if the precharge DC mode is enabled - buck direction.";
CM_ SG_ 2533851143 Precharge_dc_boost_mode_23 "Indicates if the precharge DC mode is enabled - boost direction.";
CM_ SG_ 2533851143 Rectifier_3ph_23 "Indicates if converter is in three-phase rectifier control mode.";
CM_ SG_ 2533851143 Stack_mode_23 "Indicates if converter is operating in stack mode.";
CM_ SG_ 2533851143 Master_23 "Indicates if converter is master in the stack.";
CM_ SG_ 2533851143 Slave_23 "Indicates if converter is slave in the stack.";
CM_ SG_ 2533851143 Inverter_1ph_23 "Indicates if converter is in single-phase inverter control mode.";
CM_ SG_ 2533851143 Boost_Neutral_23 "Indicates if converter is in boost control mode with neutral generation.";
CM_ SG_ 2533851143 Rectifier_1ph_23 "Indicates if converter is in single-phase rectifier control mode.";
CM_ SG_ 2533851143 Inverter_3ph_23 "Indicates if converter is in three-phase inverter control mode.";
CM_ SG_ 2533851143 Ready_23 "Indicates if converter is ready for operation.";
CM_ SG_ 2533851143 Inverter_1ph_Sync_23 "Single-phase inverter control mode with phase synchronization.";
CM_ SG_ 2533851143 Neutral_23 "Open-loop neutral generation.";
CM_ SG_ 2533851143 Rectifier_1ph_Buck_23 "Single-phase rectifier with buck on one leg.";
CM_ SG_ 2533851143 Inverter_1ph_Boost_23 "Single-phase inverter with boost on one leg.";
CM_ SG_ 2533851143 Rectifier_distributed_23 "Not available at the moment";
CM_ SG_ 2533851143 MPPT_buck_23 "Not available at the moment";
CM_ SG_ 2533851143 MPPT_boost_23 "Not available at the moment";
CM_ SG_ 2533851143 Buck_2p_float_23 "Buck in phases L1 and L2. Phase L3 is left floating (high impedance)";
CM_ SG_ 2533851143 Inverter_1ph_Distributed_23 "Single-phase inverter mode  distributed";
CM_ SG_ 2533851142 Protection_trip_internal_23 "This flagg is asserted if the interlock is open due to an internal fault condition (self-protection)";
CM_ SG_ 2533851142 Protection_trip_external_23 "This flag is asserted if the interlock is open due to an external condition received in the module.";
CM_ SG_ 2533851142 Phase_U_overcurrent_23 "Indicates an overcurrent event on Phase U. The overcurrent event is triggered when the measured phase current is over the programmed current limit.";
CM_ SG_ 2533851142 Phase_U_overvoltage_23 "Indicates an overvoltage event on Phase U. The overvoltage event is triggered when the measured phase voltage is over the programmed voltage limit.";
CM_ SG_ 2533851142 Phase_U_undervoltage_23 "Indicates an undervoltage event on Phase U. The overvoltage event is triggered when the measured phase voltage is over the programmed voltage limit.";
CM_ SG_ 2533851142 Phase_V_overvoltage_23 "Indicates an overvoltage event on Phase V. The overvoltage event is triggered when the measured phase voltage is over the programmed voltage limit.";
CM_ SG_ 2533851142 Phase_V_undervoltage_23 "Indicates an undervoltage event on Phase U. The overvoltage event is triggered when the measured phase voltage is over the programmed voltage limit.";
CM_ SG_ 2533851142 Phase_V_overcurrent_23 "Indicates an overcurrent event on Phase U. The overcurrent event is triggered when the measured phase current is over the programmed current limit.";
CM_ SG_ 2533851142 Phase_W_overvoltage_23 "Indicates an overvoltage event on Phase U. The overvoltage event is triggered when the measured phase voltage is over the programmed voltage limit.";
CM_ SG_ 2533851142 Phase_W_undervoltage_23 "Indicates an undervoltage event on Phase U. The overvoltage event is triggered when the measured phase voltage is over the programmed voltage limit.";
CM_ SG_ 2533851142 Phase_W_overcurrent_23 "Indicates an overcurrent event on Phase U. The overcurrent event is triggered when the measured phase current is over the programmed current limit.";
CM_ SG_ 2533851142 DC_undervoltage_23 "DC bus undervoltage condition. The undervoltage condition is asserted when the measured dc bus voltage is under the programmed voltage limit.";
CM_ SG_ 2533851142 DC_overvoltage_23 "DC bus overvoltage condition. The overvoltage condition is asserted when the measured dc bus voltage is over the programmed voltage limit.";
CM_ SG_ 2533851142 MOSFET_overtemperature_23 "This flag is asserted when the temperature of the MOSFET block is too high.";
CM_ SG_ 2533851142 Inductor_overtemperature_23 "This flag is asserted when the temperature of the inductor block is too high.";
CM_ SG_ 2533851142 Keep_Alive_not_served_23 "The Keep Alive feature is enabled but it was not served with the periodic message.";
CM_ SG_ 2533851142 PLL_not_locked_23 "Flag asserted when in rectifier modes, the PLL went out of lock condition";
CM_ SG_ 2533851142 Measurement_system_failure_23 "The voltages/currents measurement system is malfunctionning, and readouts are not guaranteed to be accurate.";
CM_ SG_ 2533851142 EEPROM_failure_23 "The configuration EEPROM failed to load or save the module configuration.";
CM_ SG_ 2533851139 Phase_U_23 "Phase current is the MOSFET loop current, in the branch U of the converter.";
CM_ SG_ 2533851139 Phase_V_23 "Phase current is the MOSFET loop current, in the branch V of the converter.";
CM_ SG_ 2533851139 Phase_W_23 "Phase current is the MOSFET loop current, in the branch W of the converter.";
CM_ SG_ 2533851152 Bus_current_23 "DC Bus current is possitive when current goes from input to output";
CM_ SG_ 2533851150 Phase_U_23 "Phase current is the MOSFET loop current, in the branch U of the converter.";
CM_ SG_ 2533851150 Phase_V_23 "Phase current is the MOSFET loop current, in the branch V of the converter.";
CM_ SG_ 2533851150 Phase_W_23 "Phase current is the MOSFET loop current, in the branch W of the converter.";
CM_ SG_ 2533851150 Stack_position_23 "Sender Stack position";
CM_ SG_ 2533851150 Group_ID_23 "Sender Group ID";
CM_ SG_ 2533851147 Phase_U_23 "RMS Phase current is the MOSFET loop current, in the branch U of the converter.";
CM_ SG_ 2533851147 Phase_V_23 "RMS Phase current is the MOSFET loop current, in the branch V of the converter.";
CM_ SG_ 2533851147 Phase_W_23 "RMS Phase current is the MOSFET loop current, in the branch W of the converter.";
CM_ SG_ 2533851148 Frequency_23 "Frequency of Three-Phase system";
CM_ SG_ 2533851148 Phase_23 "Phase of Three-Phase system";
CM_ SG_ 2533851141 Temp_Bridge_23 "Temperature of the MOSFET block";
CM_ SG_ 2533851141 Temp_Inductors_23 "Temperature of the inductors";
CM_ SG_ 2533851144 Phase_U_23 "The actual PWM duty cycle setpoint";
CM_ SG_ 2533851144 Phase_V_23 "The actual PWM duty cycle setpoint";
CM_ SG_ 2533851144 Phase_W_23 "The actual PWM duty cycle setpoint";
CM_ SG_ 2533851145 Current_setpoint_23 "The actual current setpoint";
CM_ SG_ 2533851145 Voltage_setpoint_23 "The actual voltage setpoint";
CM_ SG_ 2533851145 Frequency_setpoint_23 "The actual frequency setpoint";
CM_ SG_ 2533818464 Keep_Alive_Enable_23 "If set to 1, module will expect to receive this message every second repeatedly, or it will stop operation";
CM_ SG_ 2533818432 Converter_ON_23 "Enable the converter.";
CM_ SG_ 2533818432 PWM_ON_23 "Enable the PWM control mode.";
CM_ SG_ 2533818432 DC_Current_feedback_ON_23 "Enable the DC current loop";
CM_ SG_ 2533818432 AC_Current_feedback_ON_23 "Enable the AC current loop";
CM_ SG_ 2533818432 Buck_ON_23 "Enable the buck control mode.";
CM_ SG_ 2533818432 Boost_ON_23 "Enable the boost control mode.";
CM_ SG_ 2533818432 Rectifier_3ph_ON_23 "Enable the three-phase rectifier control mode.";
CM_ SG_ 2533818432 Inverter_1ph_ON_23 "Enable the single-phase inverter control mode.";
CM_ SG_ 2533818432 Rectifier_1ph_ON_23 "Enable the single-phase rectifier control mode.";
CM_ SG_ 2533818432 Boost_Neutral_ON_23 "Enable the boost control mode with neutral generation.";
CM_ SG_ 2533818432 Inverter_3ph_ON_23 "Enable the three-phase inverter control mode.";
CM_ SG_ 2533818432 Inverter_1ph_Sync_ON_23 "Single-phase inverter control mode with phase synchronization.";
CM_ SG_ 2533818432 Neutral_ON_23 "Open-loop neutral generation.";
CM_ SG_ 2533818432 Rectifier_1ph_Buck_ON_23 "Single-phase rectifier with buck on one leg.";
CM_ SG_ 2533818432 Inverter_1ph_Boost_ON_23 "Single-phase inverter with boost on one leg.";
CM_ SG_ 2533818432 Rectifier_Distributed_ON_23 "Single-phase (floating) distributed rectifier";
CM_ SG_ 2533818432 MPPT_buck_ON_23 "MPPT buck";
CM_ SG_ 2533818432 MPPT_boost_ON_23 "MPPT boost";
CM_ SG_ 2533818432 Buck_2p_float_ON_23 "Boost on L1 and L2. Floating L3 (high-impedance)";
CM_ SG_ 2533818432 Inverter_1ph_Distributed_ON_23 "Single-phase inverter mode distributed";
CM_ SG_ 2533818448 Clear_Interlock_23 "Clears the converter interlock";
CM_ SG_ 2533818448 Reset_Processor_23 "Reset the converter DSP";
CM_ SG_ 2533818448 Trip_Interlock_23 "Trip the inetrnal Interlock";
CM_ SG_ 2533818433 Reactive_current_setpoint_23 "This defines reactive current setpoint for 3-phase rectifier mode";
CM_ SG_ 2533818434 Phase_U_23 "The actual PWM duty cycle setpoint";
CM_ SG_ 2533818434 Phase_V_23 "The actual PWM duty cycle setpoint";
CM_ SG_ 2533818434 Phase_W_23 "The actual PWM duty cycle setpoint";
CM_ SG_ 2533818435 Current_setpoint_23 "Sets the output current setpoint. Active only when the current loop is enabled";
CM_ SG_ 2533818436 Voltage_setpoint_23 "Sets the output voltage setpoint. Active only when the voltage loop is enabled";
CM_ SG_ 2533818440 Frequency_setpoint_23 "Sets the frequency for single-phase and three-phase generator modes.";
CM_ SG_ 2533818441 Phase_setpoint_23 "Sets the phase for inverter control modes.";
CM_ SG_ 2533818437 Stack_position_23 "The converter position within the stack";
CM_ SG_ 2533818437 Stack_size_23 "How many PFC converters are in stack in total";
CM_ SG_ 2533818437 SN_number_23 "Unique module serial number";
CM_ SG_ 2533818416 Phase_voltage_min_23 "Minimum tolerated phase voltage";
CM_ SG_ 2533818416 Phase_voltage_max_23 "Maximum allowable phase voltage";
CM_ SG_ 2533818416 DC_voltage_min_23 "Minimum allowable dc voltage";
CM_ SG_ 2533818416 DC_voltage_max_23 "Maximum allowable dc voltage";
CM_ SG_ 2533818417 Phase_current_min_23 "Minimum allowable output current";
CM_ SG_ 2533818417 Phase_current_max_23 "Maximum allowable output current";
CM_ SG_ 2533818444 Group_ID_23 "Desired group ID for the device";
CM_ SG_ 2533851151 Group_ID_23 "Group ID of the device";
CM_ SG_ 2533818465 Factory_mode_23 "Customers MUST NOT USE this bit. If set to 1, module will enter in factory mode. ";
CM_ SG_ 2533818465 Silent_CAN_mode_23 "Customers MUST NOT USE this bit. If set to 1, module will enter in factory mode. ";
CM_ SG_ 2533818442 start_23 "Start automatic calibration. Multiplexer index must be 0!";
CM_ SG_ 2533818443 point_23 "Calibration point index.";
CM_ SG_ 2533818438 CRC_23 "Checksum of bytes 0 to 3, CRC-CCITT, corresponding to qChecksum (www.qt.io)";
CM_ SG_ 2533818439 CRC_23 "Checksum of bytes 0 to 3, CRC-CCITT, corresponding to qChecksum (www.qt.io)";
CM_ SG_ 2533851222 Current_U_High_23 "This flag is set if a hight current on U tripped the internal interlock";
CM_ SG_ 2533851222 Current_U_Low_23 "This flag is set if a low current on U tripped the internal interlock";
CM_ SG_ 2533851222 Current_V_High_23 "This flag is set if a hight current on V tripped the internal interlock";
CM_ SG_ 2533851222 Current_V_Low_23 "This flag is set if a low current on V tripped the internal interlock";
CM_ SG_ 2533851222 Current_W_High_23 "This flag is set if a hight current on W tripped the internal interlock";
CM_ SG_ 2533851222 Current_W_Low_23 "This flag is set if a low current on W tripped the internal interlock";
CM_ SG_ 2533851222 Voltage_DC_23 "This flag is set if a voltage on DC tripped the internal interlock";
CM_ SG_ 2533851222 Reboot_23 "This flag is set if a reboot tripped the internal interlock";
CM_ SG_ 2533851222 Unknown_23 "This flag the reason for the internal interlock is unknown";

BA_DEF_ BO_ "SystemMessageLongSymbol" STRING;

BA_ "SystemMessageLongSymbol" BO_ 2533818433 "AFE_Reactive_Current_Setpoint_Control_23";
BA_ "SystemMessageLongSymbol" BO_ 2533818440 "AFE_Frequency_Setpoint_Control_23";
BA_ "SystemMessageLongSymbol" BO_ 2533818480 "AFE_Rectifier_Setpoint_Control_23";
BA_ "SystemMessageLongSymbol" BO_ 2533818438 "_AFE_Calibration_Offset_Update_23";

VAL_ 2533851136 Device_type_23 7 "AFE";
VAL_ 2533851142 Protection_trip_internal_23 1 "fault";
VAL_ 2533851142 Protection_trip_external_23 1 "fault";
VAL_ 2533851142 Phase_U_overcurrent_23 1 "fault";
VAL_ 2533851142 Phase_U_overvoltage_23 1 "fault";
VAL_ 2533851142 Phase_U_undervoltage_23 1 "fault";
VAL_ 2533851142 Phase_V_overvoltage_23 1 "fault";
VAL_ 2533851142 Phase_V_undervoltage_23 1 "fault";
VAL_ 2533851142 Phase_V_overcurrent_23 1 "fault";
VAL_ 2533851142 Phase_W_overvoltage_23 1 "fault";
VAL_ 2533851142 Phase_W_undervoltage_23 1 "fault";
VAL_ 2533851142 Phase_W_overcurrent_23 1 "fault";
VAL_ 2533851142 DC_undervoltage_23 1 "fault";
VAL_ 2533851142 DC_overvoltage_23 1 "fault";
VAL_ 2533851142 MOSFET_overtemperature_23 1 "fault";
VAL_ 2533851142 Inductor_overtemperature_23 1 "fault";
VAL_ 2533851142 Keep_Alive_not_served_23 1 "fault";
VAL_ 2533851142 PLL_not_locked_23 1 "fault";
VAL_ 2533851142 NFO_23 1 "fault";
VAL_ 2533851142 Measurement_system_failure_23 1 "fault";
VAL_ 2533851142 EEPROM_failure_23 1 "fault";
VAL_ 2533851142 System_23 1 "fault";
VAL_ 2533851222 Current_U_High_23 1 "fault";
VAL_ 2533851222 Current_U_Low_23 1 "fault";
VAL_ 2533851222 Current_V_High_23 1 "fault";
VAL_ 2533851222 Current_V_Low_23 1 "fault";
VAL_ 2533851222 Current_W_High_23 1 "fault";
VAL_ 2533851222 Current_W_Low_23 1 "fault";
VAL_ 2533851222 Voltage_DC_23 1 "fault";
VAL_ 2533851222 Reboot_23 1 "fault";
VAL_ 2533851222 Unknown_23 1 "fault";
SIG_VALTYPE_ 2533851217 Current_U_23 : 1;
SIG_VALTYPE_ 2533851217 Current_V_23 : 1;
SIG_VALTYPE_ 2533851217 Current_W_23 : 1;
SIG_VALTYPE_ 2533851217 Voltage_U_23 : 1;
SIG_VALTYPE_ 2533851217 Voltage_V_23 : 1;
SIG_VALTYPE_ 2533851217 Voltage_W_23 : 1;
SIG_VALTYPE_ 2533851217 Voltage_DC_23 : 1;
SIG_VALTYPE_ 2533851218 Current_U_23 : 1;
SIG_VALTYPE_ 2533851218 Current_V_23 : 1;
SIG_VALTYPE_ 2533851218 Current_W_23 : 1;
SIG_VALTYPE_ 2533851218 Voltage_U_23 : 1;
SIG_VALTYPE_ 2533851218 Voltage_V_23 : 1;
SIG_VALTYPE_ 2533851218 Voltage_W_23 : 1;
SIG_VALTYPE_ 2533851218 Voltage_DC_23 : 1;
